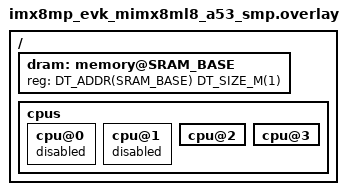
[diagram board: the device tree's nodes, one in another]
/*
 * Copyright 2025 NXP
 *
 * SPDX-License-Identifier: BSD-3-Clause
 */

#include "evkmimx8mp_ca53/rtos_memory.h"

/delete-node/ &dram;

/ {
	dram: memory@SRAM_BASE {
		reg = <DT_ADDR(SRAM_BASE) DT_SIZE_M(1)>;
	};

	cpus {
		cpu@0 {
			status = "disabled";
		};

		cpu@1 {
			status = "disabled";
		};

		cpu@2 {
			status = "okay";
		};

		cpu@3 {
			status = "okay";
		};
	};
};
